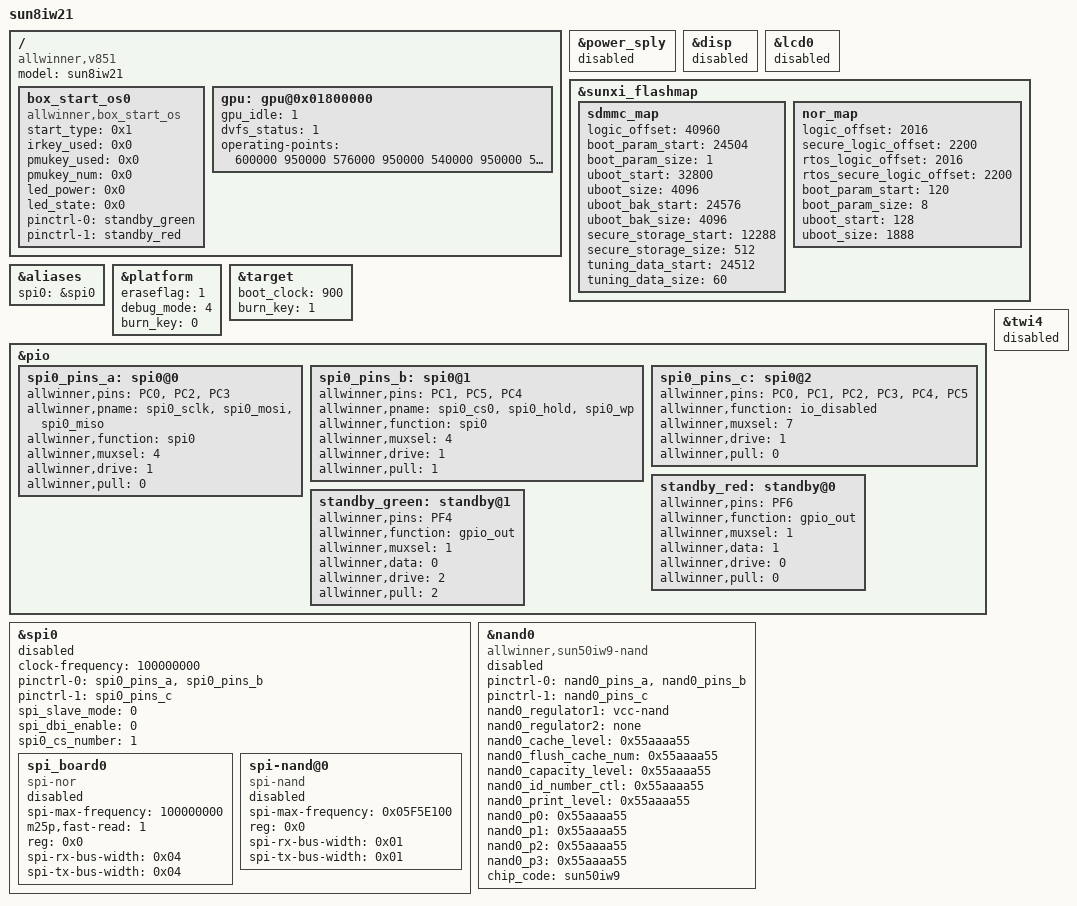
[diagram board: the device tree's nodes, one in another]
/*
 * Allwinner Technology CO., Ltd. sun8iw19p1 soc board.
 *
 * ANTARES V851SE board support.
 */

/{
	model = "sun8iw21";
	compatible = "allwinner,v851", "arm,sun8iw21p1";

	box_start_os0 {
		compatible = "allwinner,box_start_os";
		start_type = <0x1>;
		irkey_used = <0x0>;
		pmukey_used = <0x0>;
		pmukey_num = <0x0>;
		led_power = <0x0>;
		led_state = <0x0>;
		pinctrl-0 = <&standby_green>;
		pinctrl-1 = <&standby_red>;
	};
	gpu: gpu@0x01800000 {
			gpu_idle = <1>;
			dvfs_status = <1>;
			operating-points = <
				 /* KHz   uV */
				600000 950000
				576000 950000
				540000 950000
				504000 950000
				456000 950000
				420000 950000
				384000 950000
				360000 950000
				336000 950000
				306000 950000
			 >;
	};
};

&power_sply {
	status = "disabled";
};

/* Disable display subsystem */
&disp {
    status = "disabled";
};

&lcd0 {
    status = "disabled";
};

&sunxi_flashmap {
    /* Unit: Sector */
	sdmmc_map {
		logic_offset = <40960>;
		boot_param_start = <24504>;
		boot_param_size = <1>;
		uboot_start = <32800>;
		uboot_size = <4096>;
		uboot_bak_start = <24576>;
		uboot_bak_size = <4096>;
		secure_storage_start = <12288>;
		secure_storage_size = <512>;
		tuning_data_start = <24512>;
		tuning_data_size = <60>;
		status = "okay";
	};

	nor_map {
		logic_offset = <2016>;
		secure_logic_offset = <2200>;
		rtos_logic_offset = <2016>;
		rtos_secure_logic_offset = <2200>;
		boot_param_start = <120>;
		boot_param_size = <8>;
		uboot_start = <128>;
		uboot_size = <1888>;
		status = "okay";
	};
};

&aliases {
	spi0 = &spi0;
};

&platform {
	eraseflag = <1>;
	debug_mode = <4>;
	burn_key = <0>;
};

&target {
	boot_clock = <900>;    /*CPU boot frequency, Unit: MHz*/
	burn_key = <1>;
};

&pio{
	spi0_pins_a: spi0@0 {
		allwinner,pins = "PC0", "PC2", "PC3";
		allwinner,pname = "spi0_sclk", "spi0_mosi", "spi0_miso";
		allwinner,function = "spi0";
		allwinner,muxsel = <4>;
		allwinner,drive = <1>;
		allwinner,pull = <0>;
	};
	spi0_pins_b: spi0@1 {
		allwinner,pins = "PC1", "PC5", "PC4";
		allwinner,pname = "spi0_cs0", "spi0_hold", "spi0_wp";
		allwinner,function = "spi0";
		allwinner,muxsel = <4>;
		allwinner,drive = <1>;
		allwinner,pull = <1>;   // only CS should be pulled up
	};
	spi0_pins_c: spi0@2 {
		allwinner,pins = "PC0", "PC1", "PC2", "PC3", "PC4", "PC5";
		allwinner,function = "io_disabled";
		allwinner,muxsel = <7>;
		allwinner,drive = <1>;
		allwinner,pull = <0>;
	};
	standby_red: standby@0 {
		allwinner,pins = "PF6";
		allwinner,function = "gpio_out";
		allwinner,muxsel = <1>;
		allwinner,data = <1>;
		allwinner,drive = <0>;
		allwinner,pull = <0>;
	};
	standby_green: standby@1 {
		allwinner,pins = "PF4";
		allwinner,function = "gpio_out";
		allwinner,muxsel = <1>;
		allwinner,data = <0>;
		allwinner,drive = <2>;
		allwinner,pull = <2>;
	};
};


&twi4 {
	status = "disabled";
};


&spi0 {
	clock-frequency = <100000000>;
	pinctrl-0 = <&spi0_pins_a &spi0_pins_b>;
	pinctrl-1 = <&spi0_pins_c>;
	pinctrl-names = "default", "sleep";
	spi_slave_mode = <0>;
	spi_dbi_enable = <0>;
	spi0_cs_number = <1>;
	status = "disabled";

	spi_board0 {
		device_type = "spi_board0";
		compatible = "spi-nor";
		spi-max-frequency = <100000000>;
		m25p,fast-read = <1>;
		/*individual_lock;*/
		reg = <0x0>;
		spi-rx-bus-width=<0x04>;
		spi-tx-bus-width=<0x04>;
		status="disabled";
	};

	spi-nand@0 {
		compatible = "spi-nand";
		spi-max-frequency=<0x05F5E100>;
		reg = <0x0>;
		spi-rx-bus-width=<0x01>;
		spi-tx-bus-width=<0x01>;
		status="disabled";
	};
};


&nand0 {
	compatible = "allwinner,sun50iw9-nand";
	device_type = "nand0";
	//reg = <0x0 0x04011000 0x0 0x1000>;/* nand0 */
	pinctrl-names = "default", "sleep";
	pinctrl-0 = <&nand0_pins_a &nand0_pins_b>;
	pinctrl-1 = <&nand0_pins_c>;
	nand0_regulator1 = "vcc-nand";
	nand0_regulator2 = "none";
	nand0_cache_level = <0x55aaaa55>;
	nand0_flush_cache_num = <0x55aaaa55>;
	nand0_capacity_level = <0x55aaaa55>;
	nand0_id_number_ctl = <0x55aaaa55>;
	nand0_print_level = <0x55aaaa55>;
	nand0_p0 = <0x55aaaa55>;
	nand0_p1 = <0x55aaaa55>;
	nand0_p2 = <0x55aaaa55>;
	nand0_p3 = <0x55aaaa55>;
	chip_code = "sun50iw9";
	status = "disabled";
};
